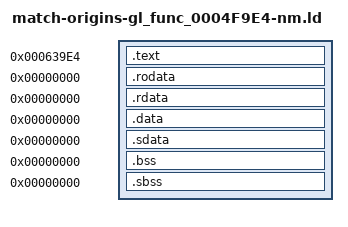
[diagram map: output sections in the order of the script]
/* Standard linker bindings; original USO identity is independently audited. */
SECTIONS {
 .text 0x639e4 : SUBALIGN(4) { *(.text) *(.text.*) }
 .rodata 0x0 : SUBALIGN(4) { *(.rodata) *(.rodata.*) }
 .rdata 0x0 : SUBALIGN(4) { *(.rdata) *(.rdata.*) }
 .data 0x0 : SUBALIGN(4) { *(.data) *(.data.*) }
 .sdata 0x0 : SUBALIGN(4) { *(.sdata) *(.sdata.*) }
 .bss 0x0 : SUBALIGN(4) { *(.bss) *(.bss.*) }
 .sbss 0x0 : SUBALIGN(4) { *(.sbss) *(.sbss.*) }
 /DISCARD/ : { *(.mdebug) *(.reginfo) *(.pdr) *(.comment) *(.MIPS.abiflags) *(.options) }
}
D_00000000 = 0x0;
D_4F9E4_head = 0x0;
D_4F9E4_itr = 0x0;
D_4F9E4_tab = 0x0;
gl_4F9E4_report = 0x0;
